VERSION ""

NS_ :

BS_:

BU_: LR_CT2 RR_CT2

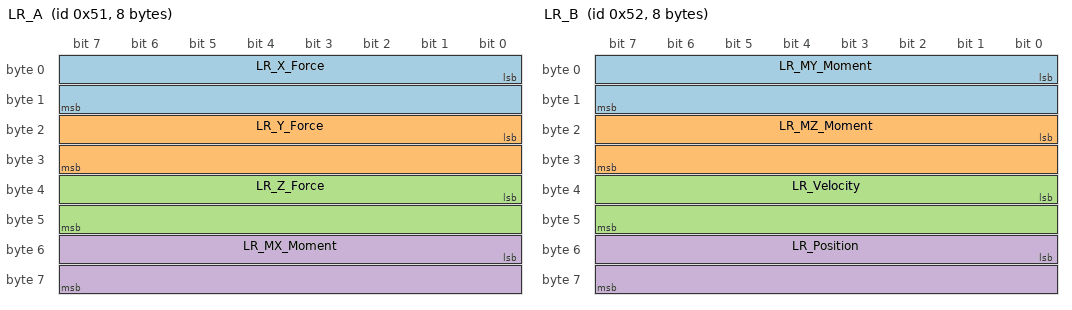
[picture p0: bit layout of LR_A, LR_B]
BO_ 81 LR_A: 8 LR_CT2
 SG_ LR_X_Force : 0|16@1- (3.08728101654053,0) [-101164|101164] "lbf" Vector__XXX
 SG_ LR_Y_Force : 16|16@1- (1.54364050827026,0) [-50582|50582] "lbf" Vector__XXX
 SG_ LR_Z_Force : 32|16@1- (3.08728101654053,0) [-101164|101164] "lbf" Vector__XXX
 SG_ LR_MX_Moment : 48|16@1- (3.15120547058105,0) [-103259|103259] "lb-ft" Vector__XXX

BO_ 82 LR_B: 8 LR_CT2
 SG_ LR_MY_Moment : 0|16@1- (3.15120547058105,0) [-103259|103259] "lb-ft" Vector__XXX
 SG_ LR_MZ_Moment : 16|16@1- (3.15120547058105,0) [-103259|103259] "lb-ft" Vector__XXX
 SG_ LR_Velocity : 32|16@1- (0.06103515625,0) [-2000|2000] "rpm" Vector__XXX
 SG_ LR_Position : 48|16@1- (0.010986328125,0) [0|360] "degrees" Vector__XXX

BO_ 83 LR_C: 4 LR_CT2
 SG_ LR_X_Acceleration : 0|16@1- (0.0030517578125,0) [-100|100] "g" Vector__XXX
 SG_ LR_Z_Acceleration : 16|16@1- (0.0030517578125,0) [-100|100] "g" Vector__XXX

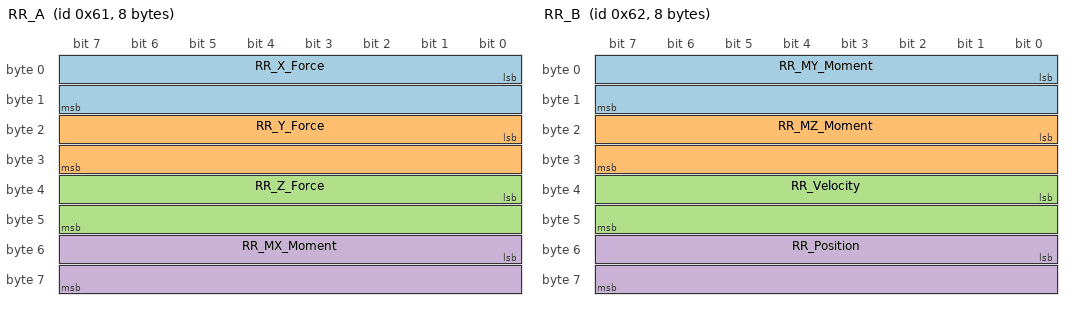
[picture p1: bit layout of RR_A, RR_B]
BO_ 97 RR_A: 8 RR_CT2
 SG_ RR_X_Force : 0|16@1- (3.08728101654053,0) [-101164|101164] "lbf" Vector__XXX
 SG_ RR_Y_Force : 16|16@1- (1.54364050827026,0) [-50582|50582] "lbf" Vector__XXX
 SG_ RR_Z_Force : 32|16@1- (3.08728101654053,0) [-101164|101164] "lbf" Vector__XXX
 SG_ RR_MX_Moment : 48|16@1- (3.15120547058105,0) [-103259|103259] "lb-ft" Vector__XXX

BO_ 98 RR_B: 8 RR_CT2
 SG_ RR_MY_Moment : 0|16@1- (3.15120547058105,0) [-103259|103259] "lb-ft" Vector__XXX
 SG_ RR_MZ_Moment : 16|16@1- (3.15120547058105,0) [-103259|103259] "lb-ft" Vector__XXX
 SG_ RR_Velocity : 32|16@1- (0.06103515625,0) [-2000|2000] "rpm" Vector__XXX
 SG_ RR_Position : 48|16@1- (0.010986328125,0) [0|360] "degrees" Vector__XXX

BO_ 99 RR_C: 4 RR_CT2
 SG_ RR_X_Acceleration : 0|16@1- (0.0030517578125,0) [-100|100] "g" Vector__XXX
 SG_ RR_Z_Acceleration : 16|16@1- (0.0030517578125,0) [-100|100] "g" Vector__XXX
